# iLF register map
Vendor: Texas Instruments
Peripheral module from a debugger description file (folder omap36xx).
Registers are 32-bit, read-write, no defined reset value unless marked. A register's access mark holds for its fields unless they carry their own. Offsets are as the file gives them; lines under a group give offsets from that group; [hi:lo] are bit positions; {n}, {i} and the like mark numbered series; 'fields as' and 'values as' point back to an identical list; <NAME> marks a mode.

## iLF
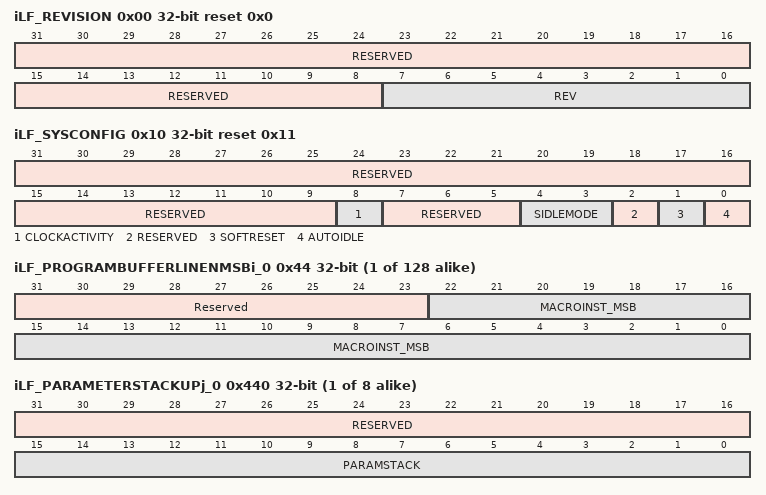
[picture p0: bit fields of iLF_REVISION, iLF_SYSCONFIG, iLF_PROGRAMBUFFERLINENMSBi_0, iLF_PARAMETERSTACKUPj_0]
0x00 iLF_REVISION ro reset 0x0 (reset mask 0xFFFFFF00) — This register contains the iLF revision code
  [31:8] RESERVED — Read returns 0
  [7:0] REV — iLF Revision[3:0] Minor Revision[7:4] Major Revision
0x10 iLF_SYSCONFIG access per field reset 0x11 — This register allows controlling various parameters of the OCP interface
  [31:9] RESERVED ro — Read returns 0.
  [8] CLOCKACTIVITY ro — Clock activity during wake up mode period. 0 - OCP clock can be switched-off.
  [7:5] RESERVED ro — read returns 0.
  [4:3] SIDLEMODE ro — Slave interface power management, req/ack control '10' = Smart-idle. Acknowledgement to an idle request is given based on the internal activity of iME
  [2] RESERVED ro — read returns 0.
  [1] SOFTRESET rw — Software reset. Set this bit to 1 to trigger the iME reset.The bit is automatically reset by the hardware. During reads, it always returns 0.
  [0] AUTOIDLE rw — Internal OCP clock gating strategy: 0: OCP clock is free running 1: Automatic OCP clock-gating strategy is applied based on the OCP interface activity
0x14 iLF_SYSSTATUS ro reset 0x0 (reset mask 0xFFFFFFFE) — The register provides status information about the module, excluding the interrupt information.
  [0] RESETDONE — Internal reset monitoring 0: Internal module reset is on-going 1: Reset completed
{0x40+8i} iLF_PROGRAMBUFFERLINENLSBi_{i} (i=0..127) — Lower part of the macro-instruction : bits [31:0]
  [31:0] MACROINST_LSB — Line i of 128, Lower part of the macro-instruction : bits [31:0]
{0x44+8i} iLF_PROGRAMBUFFERLINENMSBi_{i} access per field (i=0..127) — High part of the macro-instruction : bits [54:32]
  [31:23] Reserved ro — Read returns 0
  [22:0] MACROINST_MSB rw — Line i of 128, high part of the macro-instruction : bits [54:32]
{0x440+4i} iLF_PARAMETERSTACKUPj_{i} access per field (i=0..7) — parameter stack register file contains parameters used by program to control the iLF units.
  [31:16] RESERVED ro — Read returns 0.
  [15:0] PARAMSTACK rw — Parameter of 0 to 7
{0x460+4i} iLF_PARAMETERSTACKLWk_{i} (i=0..23) — parameter stack register file contains parameters used by program to control the iLF units.
  [31:0] PARAMSTACK — Parameter of 8 to 31
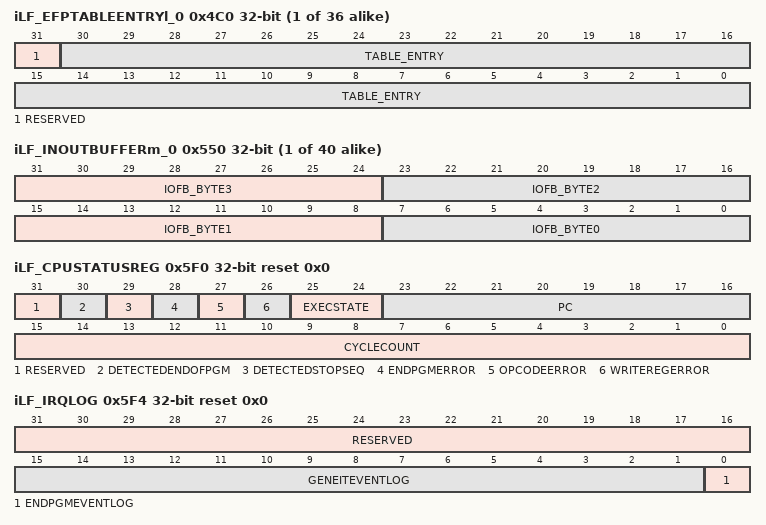
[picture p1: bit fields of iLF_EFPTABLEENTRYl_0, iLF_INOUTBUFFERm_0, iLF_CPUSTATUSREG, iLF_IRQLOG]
{0x4C0+4i} iLF_EFPTABLEENTRYl_{i} access per field (i=0..35) — EFP Table entry: contains various data organizations, depending on the standard.
  [31] RESERVED ro — Read returns 0.
  [30:0] TABLE_ENTRY rw — Entry i of the table
{0x550+4i} iLF_INOUTBUFFERm_{i} (i=0..39) — 32-bit entry in the buffer. Contains 4 8-bit fields.
  [31:24] IOFB_BYTE3 — High order byte in each entry of the IO Filter buffer
  [23:16] IOFB_BYTE2 — 3rd low order byte in each entry of the IO Filter buffer
  [15:8] IOFB_BYTE1 — 2nd low order byte in each entry of the IO Filter buffer
  [7:0] IOFB_BYTE0 — low order byte in each entry of the IO filter buffer
0x5F0 iLF_CPUSTATUSREG ro reset 0x0 — CPU Status Register provides information about the progress of the CPU execution
  [31] RESERVED — Read returns 0.
  [30] DETECTEDENDOFPGM — This bit is set to '1' when, in Debug mode, an EndPgm() instruction or the last instruction of the program buffer has been reached and it is not a LoadInstBuf() instruction.This bit is cleared by a StartSeq() command when in INITIALIZED or COMPLETED state.
  [29] DETECTEDSTOPSEQ — This bit is set to '1' when a StopSeq() has been issued and the iME is in Halted state. Execution of StopSeq() is postponed to the time when the CPU gets out of the Halted state.This bit is cleared when the StopSeq() command is effectively executed.
  [28] ENDPGMERROR — This bit is set to '1' when the last instruction of the program buffer is reached and no EndPgm() or LoadInstBuf() instruction have been detected in the program buffer.This bit is cleared by a StartSeq() command when in INITIALIZED or COMPLETED state.
  [27] OPCODEERROR — This bit is set to '1' when an unknown opcode is decoded from the main program. The following instruction of the sequence is then executed.This bit is cleared by a StartSeq() command when in INITIALIZED or COMPLETED state.
  [26] WRITEREGERROR — This bit is set to '1' when attempting to write an internal register through an OCP write, while in EXECUTING state.This bit is cleared by a StartSeq() command when in INITIALIZED or COMPLETED state.
  [25:24] EXECSTATE — Execution States:00 = Initialized,10 = Executing,01 = Halted,11 = Completed.
  [23:16] PC — Number of instruction currently executing.Bit #7 is always 0 (PC values range from 0x00 to 0x7f)
  [15:0] CYCLECOUNT — Total number of cycles executed.
0x5F4 iLF_IRQLOG ro reset 0x0 — IRQ Log register captures a one on bit 0 if the endpgm() instruction has been executed and a one on bits 1 to 15 for the first 15 GenerateIT() instructions executed (beyond 15, GenerateIT() events are logged into bit 15)
  [31:16] RESERVED — Read returns 0.
  [15:1] GENEITEVENTLOG — GenerateIT() instructions event log
  [0] ENDPGMEVENTLOG — endpgm() instruction event log.
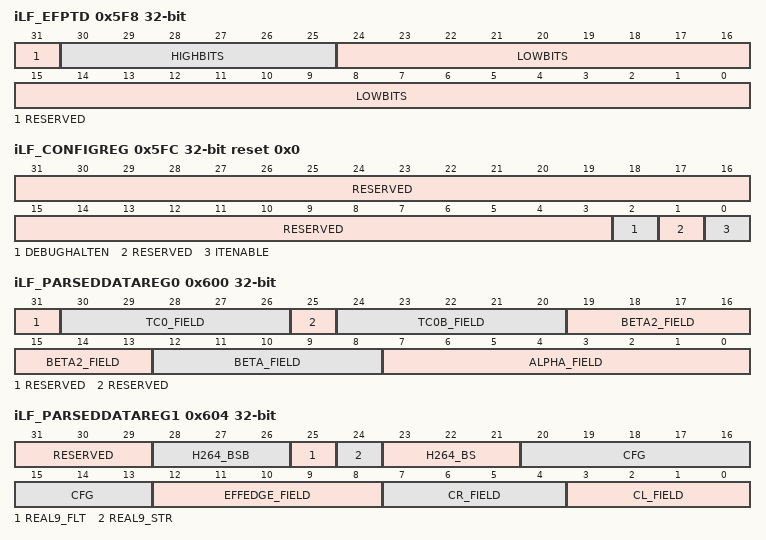
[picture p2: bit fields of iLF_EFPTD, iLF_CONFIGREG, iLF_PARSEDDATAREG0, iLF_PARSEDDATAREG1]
0x5F8 iLF_EFPTD ro — 32-bit generic data extracted from EFPT
  [31] RESERVED — read returns 0.
  [30:25] HIGHBITS — 5 bit bitfield, extracted with a second address (EFP_A2), out of EFPT
  [24:0] LOWBITS — 25 bit bitfield, extracted with a first address (EFP_A1), out of EFPT
0x5FC iLF_CONFIGREG access per field reset 0x0 — Configuration Register
  [31:3] RESERVED ro — read returns 0.
  [2] DEBUGHALTEN ro — 'Debug Halt' control bit
  [1] RESERVED ro — read returns 0.
  [0] ITENABLE rw — Interrupt Enable bit
0x600 iLF_PARSEDDATAREG0 access per field — Lower part of the Loop Filter parameters set
  [31] RESERVED ro — read returns 0.
  [30:26] TC0_FIELD rw — Tc0 parameter, 5 bits, unsigned
  [25] RESERVED rw — read returns 0.
  [24:20] TC0B_FIELD rw — Tc0B parameter, 5 bits, unsigned
  [19:13] BETA2_FIELD rw — Beta2 parameter, 7 bits, unsigned
  [12:8] BETA_FIELD rw — Beta parameter, 5 bits, unsigned
  [7:0] ALPHA_FIELD rw — Alpha parameter, 8 bits, unsigned
0x604 iLF_PARSEDDATAREG1 access per field — Mid part of the Loop Filter parameters set
  [31:29] RESERVED ro — Read returns 0.
  [28:26] H264_BSB ro — H264 Secondary Strength for Chroma
  [25] REAL9_FLT rw — Filter Flag for REAL9
  [24] REAL9_STR rw — Strong bit for REAL9
  [23:21] H264_BS rw — H264 Strength
  [20:13] CFG rw — Configuration data, 8 bits:Bits 1:0: CMR (Condition Mode), unsignedBit 2: Luma, boolean (0,1)Bits 7:3: Pquant, unsigned (WMV9/H263)
  [12:8] EFFEDGE_FIELD rw — Effective Edge Number parameter, 5 bits:Bit 4: Vertical/Horizontal orientation, boolean (0,1)Bits 3 down to 0: Effective edge number, unsigned
  [7:4] CR_FIELD rw — Clipping limit, right parameter, 4 bits, unsigned
  [3:0] CL_FIELD rw — Clipping limit, left parameter, 4 bits, unsigned
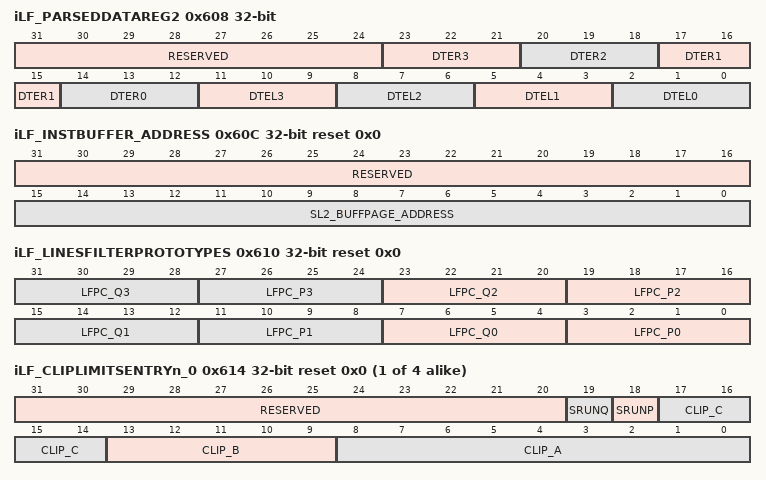
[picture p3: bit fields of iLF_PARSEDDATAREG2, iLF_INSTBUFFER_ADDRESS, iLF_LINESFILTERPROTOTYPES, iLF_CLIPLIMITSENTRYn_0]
0x608 iLF_PARSEDDATAREG2 access per field — Higher part of the Loop Filter parameters set, used for REAL9 only.
  [31:24] RESERVED ro — Read returns 0.
  [3n+14:3n+12] DTER{n} rw (n=0..3) — Dither right, set {n}
  [3n+2:3n] DTEL{n} rw (n=0..3) — Dither left, set {n}
0x60C iLF_INSTBUFFER_ADDRESS access per field reset 0x0 — The register provides status information about the module, excluding the interrupt information.
  [31:16] RESERVED ro — Read returns 0.
  [15:0] SL2_BUFFPAGE_ADDRESS rw — Page address of the Instruction buffer content in SL2 memory
0x610 iLF_LINESFILTERPROTOTYPES ro reset 0x0 — Lines Filter Prototypes : contains, for each line of pixel orthogonal to the edge, the filter prototype reference on Right and Left side of the edge: LFPC_Qi and LFPC_Pi. These references are indexes into the Filter tables of the parameter stack, to extract all filter parameters. Status register that can be used to reconstruct the filter structure used at any place, along the edge.
  [8n+7:8n+4] LFPC_Q{n} (n=0..3) — Filter on the Q side, line {n}
  [8n+3:8n] LFPC_P{n} (n=0..3) — Filter on the P side, line {n}
{0x614+4i} iLF_CLIPLIMITSENTRYn_{i} ro reset 0x0 (i=0..3) — Clip limits entry: contains clip limits, organized in 3 fields, depending on the standard Clip_A: 9 bits, signed, Clip_B: 5 bits, unsigned, Clip_C: 4 bits, unsigned.
  [31:20] RESERVED — read returns 0.
  [19] SRUNQ — 1 bit, unsignedValue when not used (according to the standard): 0
  [18] SRUNP — 1 bit, unsignedValue when not used (according to the standard): 0
  [17:14] CLIP_C — 4 bits, unsignedValue when not used (according to the standard): 15
  [13:9] CLIP_B — 5 bits, unsignedValue when not used (according to the standard): 31
  [8:0] CLIP_A — 9 bits, signedValue when not used (according to the standard): 255
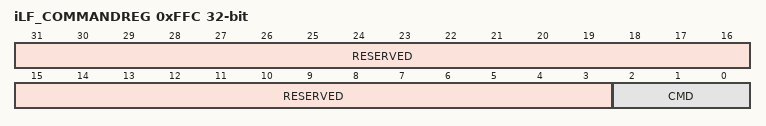
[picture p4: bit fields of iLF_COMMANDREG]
0xFFC iLF_COMMANDREG wo — iLF command register:: a write to this register decodes a command, a read returns an error. DATA/COMMAND 0x1 -> StartSeq() 0x2 -> StopSeq() 0x3 -> DbgEnable() 0x4 -> DbgDisable() 0x5 -> DbgStep() 0x6 -> Halt()
  [31:3] RESERVED — Read returns an error
  [2:0] CMD — DATA/COMMAND 0x1 -&gt; StartSeq() 0x2 -&gt; StopSeq() 0x3 -&gt; DbgEnable() 0x4 -&gt; DbgDisable() 0x5 -&gt; DbgStep() 0x6 -&gt; Halt()
